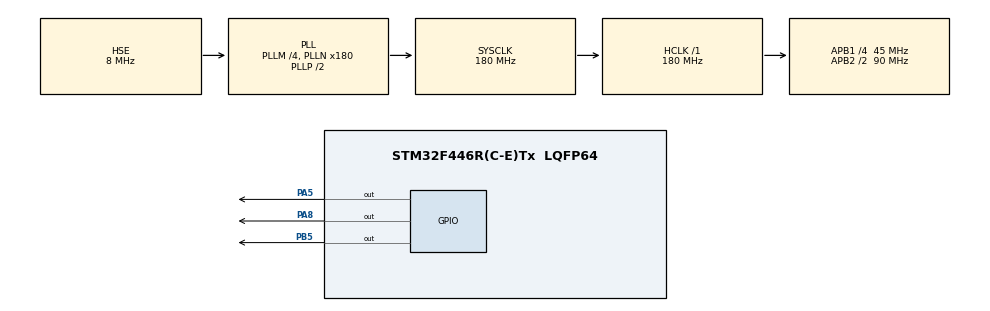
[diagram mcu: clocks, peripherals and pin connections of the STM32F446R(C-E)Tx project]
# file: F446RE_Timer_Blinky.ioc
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Mcu.Family=STM32F4
Mcu.Name=STM32F446R(C-E)Tx
Mcu.Package=LQFP64
NVIC.PriorityGroup=NVIC_PRIORITYGROUP_4
NVIC.TIM1_CC_IRQn=true\:0\:0\:false\:false\:true\:true\:true\:true
NVIC.TIM1_UP_TIM10_IRQn=true\:0\:0\:false\:false\:true\:true\:true\:true
PA13.Mode=Serial_Wire
PA13.Signal=SYS_JTMS-SWDIO
PA14.Mode=Serial_Wire
PA14.Signal=SYS_JTCK-SWCLK
PA5.Signal=GPIO_Output
PA8.Signal=GPIO_Output
PB5.Signal=GPIO_Output
PH0-OSC_IN.Mode=HSE-External-Clock-Source
PH0-OSC_IN.Signal=RCC_OSC_IN
PH1-OSC_OUT.Mode=HSE-External-Clock-Source
PH1-OSC_OUT.Signal=RCC_OSC_OUT
ProjectManager.HeapSize=0x200
ProjectManager.StackSize=0x400
ProjectManager.TargetToolchain=STM32CubeIDE
RCC.AHBFreq_Value=180000000
RCC.APB1CLKDivider=RCC_HCLK_DIV4
RCC.APB1Freq_Value=45000000
RCC.APB1TimFreq_Value=90000000
RCC.APB2CLKDivider=RCC_HCLK_DIV2
RCC.APB2Freq_Value=90000000
RCC.APB2TimFreq_Value=180000000
RCC.CortexFreq_Value=180000000
RCC.HCLKFreq_Value=180000000
RCC.HSE_VALUE=8000000
RCC.PLLM=4
RCC.PLLN=180
RCC.PLLSourceVirtual=RCC_PLLSOURCE_HSE
RCC.SYSCLKFreq_VALUE=180000000
RCC.SYSCLKSource=RCC_SYSCLKSOURCE_PLLCLK
RCC.USBFreq_Value=180000000
RCC.VCOOutputFreq_Value=360000000
TIM1.Channel-Output\ Compare1\ No\ Output=TIM_CHANNEL_1
TIM1.Period=65536-1
TIM1.Prescaler=18000-1
VP_TIM1_VS_ClockSourceINT.Mode=Internal
VP_TIM1_VS_no_output1.Mode=Output Compare1 No Output
board=custom

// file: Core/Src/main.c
/* USER CODE BEGIN Header */
/**
  ******************************************************************************
  * @file           : main.c
  * @brief          : Main program body
  ******************************************************************************
  * @attention
  *
  * Copyright (c) 2026 STMicroelectronics.
  * All rights reserved.
  *
  * This software is licensed under terms that can be found in the LICENSE file
  * in the root directory of this software component.
  * If no LICENSE file comes with this software, it is provided AS-IS.
  *
  ******************************************************************************
  */
/* USER CODE END Header */
#include "main.h"

TIM_HandleTypeDef htim1;

void SystemClock_Config(void);
static void MX_GPIO_Init(void);
static void MX_TIM1_Init(void);

/* USER CODE BEGIN 0 */

	//eg: Timer_Clock = 180 MHz / 18000-1	= 10 kHz 	->  1 count/tick lasts 100 us
	//	  Counter_Frequency = 10 khz / 65536-1 = 0.1526 Hz, ARR = 65536 counts -> meaning a Period is 6.55s

uint16_t timer_value;	//16bit var cause 16bit timer
int periodCount=0;
int halfCount=0;
uint32_t half_period = 65536/2;	//_HAL_TIM_GET_AUTORELOAD(&htim1) / 2;

//callback when timer finished a period or timer triggered dma finish the transfer
void HAL_TIM_PeriodElapsedCallback(TIM_HandleTypeDef *htim)
{
	//any timer can trigger this callback, so we need to select which timer
	if(htim == &htim1)
	{
		HAL_GPIO_TogglePin(GPIOA, GPIO_PIN_8); //red LED
		periodCount++;
	}
}

//half complete callback is triggered when you use timer to trigger dma transfer
//and the transfer is half complete, NOT when timer is at half period. Timer in interrupt cant trigger this.
//void HAL_TIM_PeriodElapsedHalfCpltCallback(TIM_HandleTypeDef *htim)
//{
//	if(htim == &htim1)
//	{
//		//wanted to trigger this at half period but this isnt the way. left this here for note
//		HAL_GPIO_TogglePin(GPIOB, GPIO_PIN_5);	//blue LEd at pb5
//		halfCount++;
//	}
//}

//to toggle the other led at half period we can use channel 1, Output Compare No Output mode
//No Output so it stays internal. Set the compare register of channel 1, CCR1 to half period (ARR/2)
//DONT FORGER TO ENABLE TIMER OC INTERRUPT!!!
void HAL_TIM_OC_DelayElapsedCallback(TIM_HandleTypeDef *htim) {
    if (htim->Instance == TIM1 && htim->Channel == HAL_TIM_ACTIVE_CHANNEL_1)
    {
        // This fires exactly at the halfway mark!
		HAL_GPIO_TogglePin(GPIOB, GPIO_PIN_5);	//blue LEd at pb5,D4
		halfCount++;
    }
}

/* USER CODE END 0 */

int main(void)
{

  /* MCU Configuration--------------------------------------------------------*/

  /* Reset of all peripherals, Initializes the Flash interface and the Systick. */
  HAL_Init();

  /* Configure the system clock */
  SystemClock_Config();

  /* Initialize all configured peripherals */
  MX_GPIO_Init();
  MX_TIM1_Init();
  /* USER CODE BEGIN 2 */

	  //Start the Base timer interrupt (Enables the Update Event for the end of period)
	  HAL_TIM_Base_Start_IT(&htim1);
	  //get current time (in us)
	  timer_value = __HAL_TIM_GET_COUNTER(&htim1);

	  //Start the Output Compare interrupt (Enables the CCR1 Event for the halfway point)
	  //TIM1->CCR1=32768;	//set compare register to half period
	  __HAL_TIM_SET_COMPARE(&htim1, TIM_CHANNEL_1, half_period);
	  HAL_TIM_OC_Start_IT(&htim1, TIM_CHANNEL_1);

  /* USER CODE END 2 */

  /* Infinite loop */
  while (1)
  {

    /* USER CODE BEGIN 3 */

	  //use timer to blink led every 1s, 10000*100us = 1s
	  if(__HAL_TIM_GET_COUNTER(&htim1)-timer_value >= 10000)
	  {
		  HAL_GPIO_TogglePin(GPIOA, GPIO_PIN_5);
		  timer_value = __HAL_TIM_GET_COUNTER(&htim1);	//update timestamp
	  }
//using timer to blick LED is non-blocking, unlike when using HAL_Delay, so we can execute
//more instructions here in between the led blink. We can also do things in timer callbacks

  }
  /* USER CODE END 3 */
}

void SystemClock_Config(void)
{
  RCC_OscInitTypeDef RCC_OscInitStruct = {0};
  RCC_ClkInitTypeDef RCC_ClkInitStruct = {0};

  /** Configure the main internal regulator output voltage
  */
  __HAL_RCC_PWR_CLK_ENABLE();
  __HAL_PWR_VOLTAGESCALING_CONFIG(PWR_REGULATOR_VOLTAGE_SCALE1);

  /** Initializes the RCC Oscillators according to the specified parameters
  * in the RCC_OscInitTypeDef structure.
  */
  RCC_OscInitStruct.OscillatorType = RCC_OSCILLATORTYPE_HSE;
  RCC_OscInitStruct.HSEState = RCC_HSE_BYPASS;
  RCC_OscInitStruct.PLL.PLLState = RCC_PLL_ON;
  RCC_OscInitStruct.PLL.PLLSource = RCC_PLLSOURCE_HSE;
  RCC_OscInitStruct.PLL.PLLM = 4;
  RCC_OscInitStruct.PLL.PLLN = 180;
  RCC_OscInitStruct.PLL.PLLP = RCC_PLLP_DIV2;
  RCC_OscInitStruct.PLL.PLLQ = 2;
  RCC_OscInitStruct.PLL.PLLR = 2;
  if (HAL_RCC_OscConfig(&RCC_OscInitStruct) != HAL_OK)
  {
    Error_Handler();
  }

  /** Activate the Over-Drive mode
  */
  if (HAL_PWREx_EnableOverDrive() != HAL_OK)
  {
    Error_Handler();
  }

  /** Initializes the CPU, AHB and APB buses clocks
  */
  RCC_ClkInitStruct.ClockType = RCC_CLOCKTYPE_HCLK|RCC_CLOCKTYPE_SYSCLK
                              |RCC_CLOCKTYPE_PCLK1|RCC_CLOCKTYPE_PCLK2;
  RCC_ClkInitStruct.SYSCLKSource = RCC_SYSCLKSOURCE_PLLCLK;
  RCC_ClkInitStruct.AHBCLKDivider = RCC_SYSCLK_DIV1;
  RCC_ClkInitStruct.APB1CLKDivider = RCC_HCLK_DIV4;
  RCC_ClkInitStruct.APB2CLKDivider = RCC_HCLK_DIV2;

  if (HAL_RCC_ClockConfig(&RCC_ClkInitStruct, FLASH_LATENCY_5) != HAL_OK)
  {
    Error_Handler();
  }
}

static void MX_TIM1_Init(void)
{

  TIM_ClockConfigTypeDef sClockSourceConfig = {0};
  TIM_MasterConfigTypeDef sMasterConfig = {0};
  TIM_OC_InitTypeDef sConfigOC = {0};
  TIM_BreakDeadTimeConfigTypeDef sBreakDeadTimeConfig = {0};

  htim1.Instance = TIM1;
  htim1.Init.Prescaler = 18000-1;
  htim1.Init.CounterMode = TIM_COUNTERMODE_UP;
  htim1.Init.Period = 65536-1;
  htim1.Init.ClockDivision = TIM_CLOCKDIVISION_DIV1;
  htim1.Init.RepetitionCounter = 0;
  htim1.Init.AutoReloadPreload = TIM_AUTORELOAD_PRELOAD_DISABLE;
  if (HAL_TIM_Base_Init(&htim1) != HAL_OK)
  {
    Error_Handler();
  }
  sClockSourceConfig.ClockSource = TIM_CLOCKSOURCE_INTERNAL;
  if (HAL_TIM_ConfigClockSource(&htim1, &sClockSourceConfig) != HAL_OK)
  {
    Error_Handler();
  }
  if (HAL_TIM_OC_Init(&htim1) != HAL_OK)
  {
    Error_Handler();
  }
  sMasterConfig.MasterOutputTrigger = TIM_TRGO_RESET;
  sMasterConfig.MasterSlaveMode = TIM_MASTERSLAVEMODE_DISABLE;
  if (HAL_TIMEx_MasterConfigSynchronization(&htim1, &sMasterConfig) != HAL_OK)
  {
    Error_Handler();
  }
  sConfigOC.OCMode = TIM_OCMODE_TIMING;
  sConfigOC.Pulse = 0;
  sConfigOC.OCPolarity = TIM_OCPOLARITY_HIGH;
  sConfigOC.OCNPolarity = TIM_OCNPOLARITY_HIGH;
  sConfigOC.OCFastMode = TIM_OCFAST_DISABLE;
  sConfigOC.OCIdleState = TIM_OCIDLESTATE_RESET;
  sConfigOC.OCNIdleState = TIM_OCNIDLESTATE_RESET;
  if (HAL_TIM_OC_ConfigChannel(&htim1, &sConfigOC, TIM_CHANNEL_1) != HAL_OK)
  {
    Error_Handler();
  }
  sBreakDeadTimeConfig.OffStateRunMode = TIM_OSSR_DISABLE;
  sBreakDeadTimeConfig.OffStateIDLEMode = TIM_OSSI_DISABLE;
  sBreakDeadTimeConfig.LockLevel = TIM_LOCKLEVEL_OFF;
  sBreakDeadTimeConfig.DeadTime = 0;
  sBreakDeadTimeConfig.BreakState = TIM_BREAK_DISABLE;
  sBreakDeadTimeConfig.BreakPolarity = TIM_BREAKPOLARITY_HIGH;
  sBreakDeadTimeConfig.AutomaticOutput = TIM_AUTOMATICOUTPUT_DISABLE;
  if (HAL_TIMEx_ConfigBreakDeadTime(&htim1, &sBreakDeadTimeConfig) != HAL_OK)
  {
    Error_Handler();
  }

}

static void MX_GPIO_Init(void)
{
  GPIO_InitTypeDef GPIO_InitStruct = {0};

  /* GPIO Ports Clock Enable */
  __HAL_RCC_GPIOH_CLK_ENABLE();
  __HAL_RCC_GPIOA_CLK_ENABLE();
  __HAL_RCC_GPIOB_CLK_ENABLE();

  /*Configure GPIO pin Output Level */
  HAL_GPIO_WritePin(GPIOA, GPIO_PIN_5|GPIO_PIN_8, GPIO_PIN_RESET);

  /*Configure GPIO pin Output Level */
  HAL_GPIO_WritePin(GPIOB, GPIO_PIN_5, GPIO_PIN_RESET);

  /*Configure GPIO pins : PA5 PA8 */
  GPIO_InitStruct.Pin = GPIO_PIN_5|GPIO_PIN_8;
  GPIO_InitStruct.Mode = GPIO_MODE_OUTPUT_PP;
  GPIO_InitStruct.Pull = GPIO_NOPULL;
  GPIO_InitStruct.Speed = GPIO_SPEED_FREQ_LOW;
  HAL_GPIO_Init(GPIOA, &GPIO_InitStruct);

  /*Configure GPIO pin : PB5 */
  GPIO_InitStruct.Pin = GPIO_PIN_5;
  GPIO_InitStruct.Mode = GPIO_MODE_OUTPUT_PP;
  GPIO_InitStruct.Pull = GPIO_NOPULL;
  GPIO_InitStruct.Speed = GPIO_SPEED_FREQ_LOW;
  HAL_GPIO_Init(GPIOB, &GPIO_InitStruct);

}

void Error_Handler(void)
{
  __disable_irq();
  while (1)
  {
  }
}
